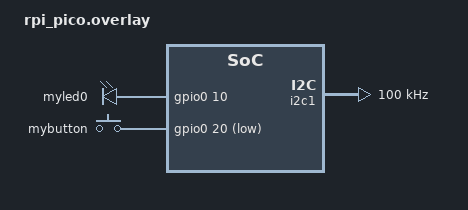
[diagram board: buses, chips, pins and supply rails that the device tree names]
#include <zephyr/dt-bindings/adc/adc.h>

/ {
	aliases {
		ledsoil = &myled0;
		soilpin = &mybutton;
	};
	leds {
		compatible = "gpio-leds";
		myled0: myled0 {
		   gpios = <&gpio0 10 GPIO_ACTIVE_HIGH>;
		};
	};
	buttons {
		compatible = "gpio-keys";
		mybutton: mybutton {
		   gpios = <&gpio0 20 (GPIO_ACTIVE_LOW|GPIO_PULL_UP)>;
		};
	};
};

&pinctrl {
	i2c1_default: i2c1_default {
		group1 {
			pinmux = <I2C1_SDA_P2>, <I2C1_SCL_P3>;       
			input-enable;
			input-schmitt-enable;
		};
	};
};
&i2c1 {
	clock-frequency = <I2C_BITRATE_STANDARD>;
	status = "okay";
	pinctrl-0 = <&i2c1_default>;
	pinctrl-names = "default";
};
